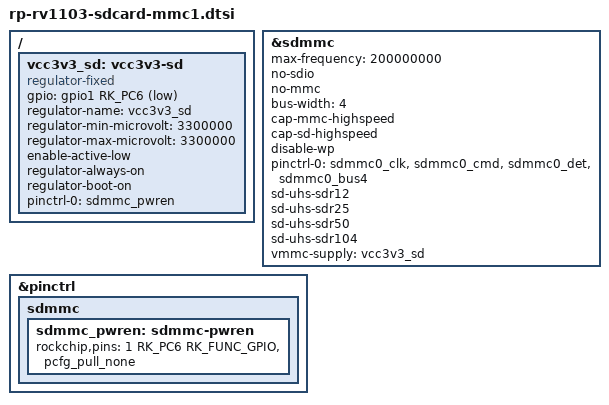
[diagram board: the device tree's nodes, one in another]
/{
    vcc3v3_sd: vcc3v3-sd {
        compatible = "regulator-fixed";
        gpio = <&gpio1 RK_PC6 GPIO_ACTIVE_LOW>;
        regulator-name = "vcc3v3_sd";
        regulator-min-microvolt = <3300000>;
        regulator-max-microvolt = <3300000>;
        enable-active-low;
        regulator-always-on;
        regulator-boot-on;
		pinctrl-names = "default";
        pinctrl-0 = <&sdmmc_pwren>;
    };
};
&sdmmc {
    max-frequency = <200000000>;
    no-sdio;
    no-mmc;
    bus-width = <4>;
    cap-mmc-highspeed;
    cap-sd-highspeed;
    disable-wp;
    pinctrl-names = "default";
    pinctrl-0 = <&sdmmc0_clk &sdmmc0_cmd &sdmmc0_det &sdmmc0_bus4>;
    sd-uhs-sdr12;
    sd-uhs-sdr25;
    sd-uhs-sdr50;
    sd-uhs-sdr104;
    vmmc-supply = <&vcc3v3_sd>;
    //vqmmc-supply = <&vccio_sd>;
    status = "okay";
};

&pinctrl {
    sdmmc {
        /omit-if-no-ref/
        sdmmc_pwren: sdmmc-pwren {
            rockchip,pins = <1 RK_PC6 RK_FUNC_GPIO &pcfg_pull_none>;
        };
    };
};
